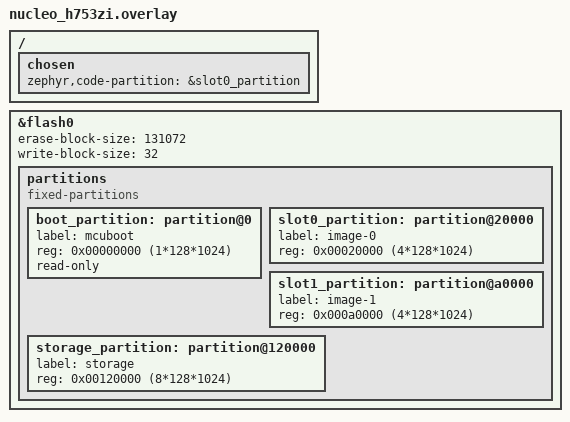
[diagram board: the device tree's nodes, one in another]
/ {
    chosen {
        zephyr,code-partition = &slot0_partition;
    };
};

&flash0 {
    erase-block-size = <131072>;
    write-block-size = <32>;

    /delete-node/ partitions;
    partitions {
        compatible = "fixed-partitions";
        #address-cells = <1>;
        #size-cells = <1>;

        boot_partition: partition@0 {
            label = "mcuboot";
            reg = <0x00000000 (1*128*1024)>;
            read-only;
        };
        slot0_partition: partition@20000 {
            label = "image-0";
            reg = <0x00020000 (4*128*1024)>;
        };
        slot1_partition: partition@a0000 {
            label = "image-1";
            reg = <0x000a0000 (4*128*1024)>;
        };
        storage_partition: partition@120000 {
            label = "storage";
            reg = <0x00120000 (8*128*1024)>;
        };
    };
};
